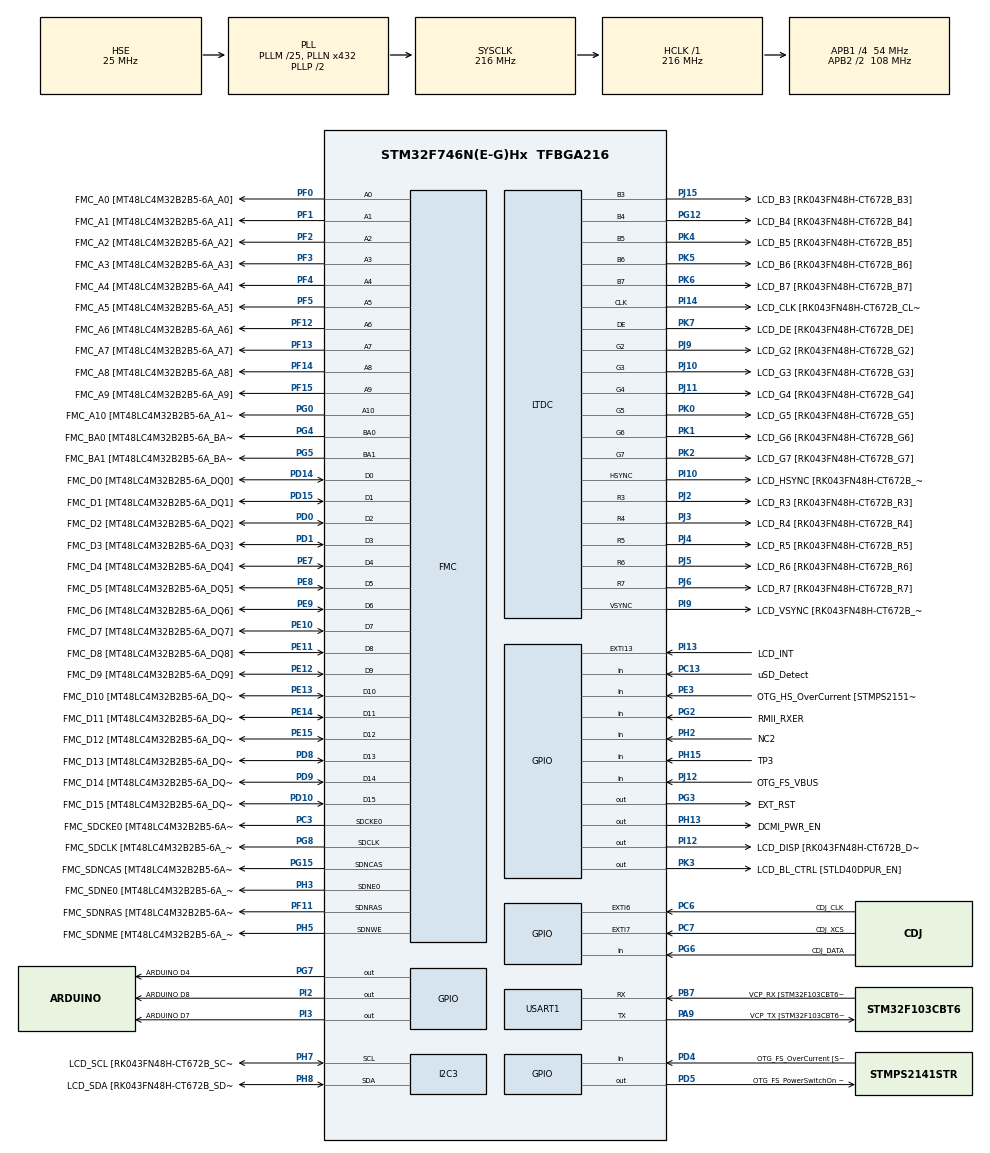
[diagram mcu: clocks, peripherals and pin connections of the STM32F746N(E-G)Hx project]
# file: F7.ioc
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CORTEX_M7.CPU_DCache=Enabled
CORTEX_M7.CPU_ICache=Enabled
FMC.CASLatency1=FMC_SDRAM_CAS_LATENCY_2
FMC.ExitSelfRefreshDelay1=6
FMC.LoadToActiveDelay1=2
FMC.RCDDelay1=2
FMC.RPDelay1=2
FMC.ReadBurst1=FMC_SDRAM_RBURST_ENABLE
FMC.RowCycleDelay1=6
FMC.SelfRefreshTime1=4
FMC.WriteRecoveryTime1=2
I2C3.Timing=0x20404768
LTDC.ActiveH=272
LTDC.ActiveW=480
LTDC.Alpha_L0=255
LTDC.Alpha_L1=255
LTDC.HBP=13
LTDC.HFP=32
LTDC.HSync=41
LTDC.Layers=1
LTDC.VSync=10
LTDC.WindowX1_L0=239
LTDC.WindowX1_L1=239
LTDC.WindowY1_L0=239
LTDC.WindowY1_L1=239
Mcu.Family=STM32F7
Mcu.Name=STM32F746N(E-G)Hx
Mcu.Package=TFBGA216
NVIC.EXTI9_5_IRQn=true\:0\:0\:false\:false\:true
NVIC.PriorityGroup=NVIC_PRIORITYGROUP_4
PA0/WKUP.GPIO_Label=ARDUINO A0
PA0/WKUP.GPIO_Mode=GPIO_MODE_ANALOG
PA0/WKUP.GPIO_PuPd=GPIO_NOPULL
PA0/WKUP.Signal=ADCx_IN0
PA1.GPIO_Label=RMII_REF_CLK [LAN8742A-CZ-TR_REFCLK0]
PA1.Signal=ETH_REF_CLK
PA10.GPIO_Label=OTG_FS_ID
PA10.Signal=USB_OTG_FS_ID
PA11.GPIO_Label=OTG_FS_N
PA11.Signal=USB_OTG_FS_DM
PA12.GPIO_Label=OTG_FS_P
PA12.Signal=USB_OTG_FS_DP
PA13.GPIO_Label=SWDIO
PA13.Signal=SYS_JTMS-SWDIO
PA14.GPIO_Label=SWCLK
PA14.Signal=SYS_JTCK-SWCLK
PA15.GPIO_Label=ARDUINO PWM/D9
PA15.GPIO_ModeDefaultPP=GPIO_MODE_AF_PP
PA15.GPIO_PuPd=GPIO_NOPULL
PA15.GPIO_Speed=GPIO_SPEED_FREQ_LOW
PA15.Signal=S_TIM2_CH1_ETR
PA2.GPIO_Label=RMII_MDIO [LAN8742A-CZ-TR_MDIO]
PA2.Signal=ETH_MDIO
PA3.GPIO_Label=ULPI_D0 [USB3320C-EZK_D0]
PA3.Signal=USB_OTG_HS_ULPI_D0
PA4.GPIO_Label=DCMI_HSYNC
PA4.Signal=DCMI_HSYNC
PA5.GPIO_Label=ULPI_CLK [USB3320C-EZK_CLKOUT]
PA5.Signal=USB_OTG_HS_ULPI_CK
PA6.Signal=DCMI_PIXCLK
PA7.GPIO_Label=RMII_CRS_DV [LAN8742A-CZ-TR_CRS_DV]
PA7.Signal=ETH_CRS_DV
PA8.GPIO_Label=ARDUINO PWM/D5
PA8.GPIO_ModeDefaultPP=GPIO_MODE_AF_PP
PA8.GPIO_PuPd=GPIO_NOPULL
PA8.GPIO_Speed=GPIO_SPEED_FREQ_LOW
PA8.Signal=S_TIM1_CH1
PA9.GPIO_Label=VCP_TX [STM32F103CBT6_PA3]
PA9.GPIO_Mode=GPIO_MODE_AF_PP
PA9.GPIO_PuPd=GPIO_NOPULL
PA9.GPIO_Speed=GPIO_SPEED_FREQ_LOW
PA9.Mode=Asynchronous
PA9.Signal=USART1_TX
PB0.GPIO_Label=ULPI_D1 [USB3320C-EZK_D1]
PB0.Signal=USB_OTG_HS_ULPI_D1
PB1.GPIO_Label=ULPI_D2 [USB3320C-EZK_D2]
PB1.Signal=USB_OTG_HS_ULPI_D2
PB10.GPIO_Label=ULPI_D3 [USB3320C-EZK_D3]
PB10.Signal=USB_OTG_HS_ULPI_D3
PB11.GPIO_Label=ULPI_D4 [USB3320C-EZK_D4]
PB11.Signal=USB_OTG_HS_ULPI_D4
PB12.GPIO_Label=ULPI_D5 [USB3320C-EZK_D5]
PB12.Signal=USB_OTG_HS_ULPI_D5
PB13.GPIO_Label=ULPI_D6 [USB3320C-EZK_D6]
PB13.Signal=USB_OTG_HS_ULPI_D6
PB14.GPIO_Label=ARDUINO MISO/D12
PB14.GPIO_Mode=GPIO_MODE_AF_PP
PB14.GPIO_PuPd=GPIO_NOPULL
PB14.GPIO_Speed=GPIO_SPEED_FREQ_LOW
PB14.Signal=SPI2_MISO
PB15.GPIO_Label=ARDUINO MOSI/PWM/D11
PB15.GPIO_Mode=GPIO_MODE_AF_PP
PB15.GPIO_PuPd=GPIO_NOPULL
PB15.GPIO_Speed=GPIO_SPEED_FREQ_LOW
PB15.Signal=SPI2_MOSI
PB2.Signal=QUADSPI_CLK
PB3.GPIO_Label=SWO
PB3.Signal=SYS_JTDO-SWO
PB4.GPIO_Label=ARDUINO PWM/D3
PB4.GPIO_ModeDefaultPP=GPIO_MODE_AF_PP
PB4.GPIO_PuPd=GPIO_NOPULL
PB4.GPIO_Speed=GPIO_SPEED_FREQ_LOW
PB4.Signal=S_TIM3_CH1
PB5.GPIO_Label=ULPI_D7 [USB3320C-EZK_D7]
PB5.Signal=USB_OTG_HS_ULPI_D7
PB6.GPIO_Label=QSPI_NCS [N25Q128A13EF840E_S]
PB6.Signal=QUADSPI_BK1_NCS
PB7.GPIO_Label=VCP_RX [STM32F103CBT6_PA2]
PB7.GPIO_Mode=GPIO_MODE_AF_PP
PB7.GPIO_PuPd=GPIO_NOPULL
PB7.GPIO_Speed=GPIO_SPEED_FREQ_LOW
PB7.Mode=Asynchronous
PB7.Signal=USART1_RX
PB8.GPIO_Label=ARDUINO SCL/D15
PB8.GPIO_Mode=GPIO_MODE_AF_OD
PB8.GPIO_PuPd=GPIO_NOPULL
PB8.GPIO_Speed=GPIO_SPEED_FREQ_LOW
PB8.Signal=I2C1_SCL
PB9.GPIO_Label=ARDUINO SDA/D14
PB9.GPIO_Mode=GPIO_MODE_AF_OD
PB9.GPIO_PuPd=GPIO_NOPULL
PB9.GPIO_Speed=GPIO_SPEED_FREQ_LOW
PB9.Signal=I2C1_SDA
PC0.GPIO_Label=ULPI_STP [USB3320C-EZK_STP]
PC0.Signal=USB_OTG_HS_ULPI_STP
PC1.GPIO_Label=RMII_MDC [LAN8742A-CZ-TR_MDC]
PC1.Signal=ETH_MDC
PC10.GPIO_Label=SDMMC_D2
PC10.Signal=SDMMC1_D2
PC11.GPIO_Label=SDMMC_D3
PC11.Signal=SDMMC1_D3
PC12.GPIO_Label=SDMMC_CK
PC12.Signal=SDMMC1_CK
PC13.GPIO_Label=uSD_Detect
PC13.Signal=GPIO_Input
PC14/OSC32_IN.GPIO_Label=RCC_OSC32_IN
PC14/OSC32_IN.Signal=RCC_OSC32_IN
PC15/OSC32_OUT.GPIO_Label=RCC_OSC32_OUT
PC15/OSC32_OUT.Signal=RCC_OSC32_OUT
PC2.GPIO_Label=ULPI_DIR [USB3320C-EZK_DIR]
PC2.Signal=USB_OTG_HS_ULPI_DIR
PC3.GPIO_Label=FMC_SDCKE0 [MT48LC4M32B2B5-6A_CKE]
PC3.Mode=SdramChipSelect1_1
PC3.Signal=FMC_SDCKE0
PC4.GPIO_Label=RMII_RXD0 [LAN8742A-CZ-TR_RXD0]
PC4.Signal=ETH_RXD0
PC5.GPIO_Label=RMII_RXD1 [LAN8742A-CZ-TR_RXD1]
PC5.Signal=ETH_RXD1
PC6.GPIO_Label=CDJ_CLK
PC6.GPIO_ModeDefaultEXTI=GPIO_MODE_IT_RISING
PC6.GPIO_PuPd=GPIO_PULLUP
PC6.Signal=GPXTI6
PC7.GPIO_Label=CDJ_XCS
PC7.GPIO_ModeDefaultEXTI=GPIO_MODE_IT_FALLING
PC7.GPIO_PuPd=GPIO_PULLUP
PC7.Signal=GPXTI7
PC8.Signal=SDMMC1_D0
PC9.Signal=SDMMC1_D1
PD0.GPIO_Label=FMC_D2 [MT48LC4M32B2B5-6A_DQ2]
PD0.Signal=FMC_D2_DA2
PD1.GPIO_Label=FMC_D3 [MT48LC4M32B2B5-6A_DQ3]
PD1.Signal=FMC_D3_DA3
PD10.GPIO_Label=FMC_D15 [MT48LC4M32B2B5-6A_DQ15]
PD10.Signal=FMC_D15_DA15
PD11.GPIO_Label=QSPI_D0 [N25Q128A13EF840E_DQ0]
PD11.Signal=QUADSPI_BK1_IO0
PD12.GPIO_Label=QSPI_D1 [N25Q128A13EF840E_DQ1]
PD12.Signal=QUADSPI_BK1_IO1
PD13.GPIO_Label=QSPI_D3 [N25Q128A13EF840E_DQ3]
PD13.Signal=QUADSPI_BK1_IO3
PD14.GPIO_Label=FMC_D0 [MT48LC4M32B2B5-6A_DQ0]
PD14.Signal=FMC_D0_DA0
PD15.GPIO_Label=FMC_D1 [MT48LC4M32B2B5-6A_DQ1]
PD15.Signal=FMC_D1_DA1
PD2.GPIO_Label=SDMMC_D0
PD2.Signal=SDMMC1_CMD
PD3.GPIO_Label=DCMI_D5
PD3.Signal=DCMI_D5
PD4.GPIO_Label=OTG_FS_OverCurrent [STMPS2141STR_Fault]
PD4.Signal=GPIO_Input
PD5.GPIO_Label=OTG_FS_PowerSwitchOn [STMPS2141STR_EN]
PD5.PinState=GPIO_PIN_SET
PD5.Signal=GPIO_Output
PD7.GPIO_Label=SPDIF_RX0 [74LVC1G04SE_4]
PD7.Signal=SPDIFRX_IN0
PD8.GPIO_Label=FMC_D13 [MT48LC4M32B2B5-6A_DQ13]
PD8.Signal=FMC_D13_DA13
PD9.GPIO_Label=FMC_D14 [MT48LC4M32B2B5-6A_DQ14]
PD9.Signal=FMC_D14_DA14
PE0.GPIO_Label=FMC_NBL0 [MT48LC4M32B2B5-6A_DQM0]
PE0.Signal=FMC_NBL0
PE1.GPIO_Label=FMC_NBL1 [MT48LC4M32B2B5-6A_DQM1]
PE1.Signal=FMC_NBL1
PE10.GPIO_Label=FMC_D7 [MT48LC4M32B2B5-6A_DQ7]
PE10.Signal=FMC_D7_DA7
PE11.GPIO_Label=FMC_D8 [MT48LC4M32B2B5-6A_DQ8]
PE11.Signal=FMC_D8_DA8
PE12.GPIO_Label=FMC_D9 [MT48LC4M32B2B5-6A_DQ9]
PE12.Signal=FMC_D9_DA9
PE13.GPIO_Label=FMC_D10 [MT48LC4M32B2B5-6A_DQ10]
PE13.Signal=FMC_D10_DA10
PE14.GPIO_Label=FMC_D11 [MT48LC4M32B2B5-6A_DQ11]
PE14.Signal=FMC_D11_DA11
PE15.GPIO_Label=FMC_D12 [MT48LC4M32B2B5-6A_DQ12]
PE15.Signal=FMC_D12_DA12
PE2.GPIO_Label=QSPI_D2 [N25Q128A13EF840E_DQ2]
PE2.Signal=QUADSPI_BK1_IO2
PE3.GPIO_Label=OTG_HS_OverCurrent [STMPS2151STR_FAULT]
PE3.Signal=GPIO_Input
PE4.GPIO_Label=LCD_B0 [RK043FN48H-CT672B_B0]
PE4.Signal=LTDC_B0
PE5.GPIO_Label=DCMI_D6
PE5.Signal=DCMI_D6
PE6.GPIO_Label=DCMI_D7
PE6.Signal=DCMI_D7
PE7.GPIO_Label=FMC_D4 [MT48LC4M32B2B5-6A_DQ4]
PE7.Signal=FMC_D4_DA4
PE8.GPIO_Label=FMC_D5 [MT48LC4M32B2B5-6A_DQ5]
PE8.Signal=FMC_D5_DA5
PE9.GPIO_Label=FMC_D6 [MT48LC4M32B2B5-6A_DQ6]
PE9.Signal=FMC_D6_DA6
PF0.GPIO_Label=FMC_A0 [MT48LC4M32B2B5-6A_A0]
PF0.Signal=FMC_A0
PF1.GPIO_Label=FMC_A1 [MT48LC4M32B2B5-6A_A1]
PF1.Signal=FMC_A1
PF10.GPIO_Label=ARDUINO A1
PF10.GPIO_Mode=GPIO_MODE_ANALOG
PF10.GPIO_PuPd=GPIO_NOPULL
PF10.Signal=ADC3_IN8
PF11.GPIO_Label=FMC_SDNRAS [MT48LC4M32B2B5-6A_RAS]
PF11.Signal=FMC_SDNRAS
PF12.GPIO_Label=FMC_A6 [MT48LC4M32B2B5-6A_A6]
PF12.Signal=FMC_A6
PF13.GPIO_Label=FMC_A7 [MT48LC4M32B2B5-6A_A7]
PF13.Signal=FMC_A7
PF14.GPIO_Label=FMC_A8 [MT48LC4M32B2B5-6A_A8]
PF14.Signal=FMC_A8
PF15.GPIO_Label=FMC_A9 [MT48LC4M32B2B5-6A_A9]
PF15.Signal=FMC_A9
PF2.GPIO_Label=FMC_A2 [MT48LC4M32B2B5-6A_A2]
PF2.Signal=FMC_A2
PF3.GPIO_Label=FMC_A3 [MT48LC4M32B2B5-6A_A3]
PF3.Signal=FMC_A3
PF4.GPIO_Label=FMC_A4 [MT48LC4M32B2B5-6A_A4]
PF4.Signal=FMC_A4
PF5.GPIO_Label=FMC_A5 [MT48LC4M32B2B5-6A_A5]
PF5.Signal=FMC_A5
PF6.GPIO_Label=ARDUINO A5
PF6.GPIO_Mode=GPIO_MODE_ANALOG
PF6.GPIO_PuPd=GPIO_NOPULL
PF6.Signal=ADC3_IN4
PF7.GPIO_Label=ARDUINO A4
PF7.GPIO_Mode=GPIO_MODE_ANALOG
PF7.GPIO_PuPd=GPIO_NOPULL
PF7.Signal=ADC3_IN5
PF8.GPIO_Label=ARDUINO A3
PF8.GPIO_Mode=GPIO_MODE_ANALOG
PF8.GPIO_PuPd=GPIO_NOPULL
PF8.Signal=ADC3_IN6
PF9.GPIO_Label=ARDUINO A2
PF9.GPIO_Mode=GPIO_MODE_ANALOG
PF9.GPIO_PuPd=GPIO_NOPULL
PF9.Signal=ADC3_IN7
PG0.GPIO_Label=FMC_A10 [MT48LC4M32B2B5-6A_A10]
PG0.Signal=FMC_A10
PG1.GPIO_Label=FMC_A11 [MT48LC4M32B2B5-6A_A11]
PG1.Signal=FMC_A11
PG10.GPIO_Label=SAI2_SDB [WM8994ECS/R_ADCDAT1]
PG10.Signal=SAI2_SD_B
PG11.GPIO_Label=RMII_TX_EN [LAN8742A-CZ-TR_TXEN]
PG11.Signal=ETH_TX_EN
PG12.GPIO_Label=LCD_B4 [RK043FN48H-CT672B_B4]
PG12.Mode=RGB565
PG12.Signal=LTDC_B4
PG13.GPIO_Label=RMII_TXD0 [LAN8742A-CZ-TR_TXD0]
PG13.Signal=ETH_TXD0
PG14.GPIO_Label=RMII_TXD1 [LAN8742A-CZ-TR_TXD1]
PG14.Signal=ETH_TXD1
PG15.GPIO_Label=FMC_SDNCAS [MT48LC4M32B2B5-6A_CAS]
PG15.Signal=FMC_SDNCAS
PG2.GPIO_Label=RMII_RXER
PG2.Signal=GPIO_Input
PG3.GPIO_Label=EXT_RST
PG3.Signal=GPIO_Output
PG4.GPIO_Label=FMC_BA0 [MT48LC4M32B2B5-6A_BA0]
PG4.Signal=FMC_A14_BA0
PG5.GPIO_Label=FMC_BA1 [MT48LC4M32B2B5-6A_BA1]
PG5.Signal=FMC_A15_BA1
PG6.GPIO_Label=CDJ_DATA
PG6.GPIO_PuPd=GPIO_PULLUP
PG6.Signal=GPIO_Input
PG7.GPIO_Label=ARDUINO D4
PG7.Signal=GPIO_Output
PG8.GPIO_Label=FMC_SDCLK [MT48LC4M32B2B5-6A_CLK]
PG8.Signal=FMC_SDCLK
PG9.GPIO_Label=DCMI_VSYNC
PG9.Signal=DCMI_VSYNC
PH0/OSC_IN.GPIO_Label=OSC_25M [NZ2520SB-25.00M_OUT]
PH0/OSC_IN.Mode=HSE-External-Oscillator
PH0/OSC_IN.Signal=RCC_OSC_IN
PH1/OSC_OUT.Mode=HSE-External-Oscillator
PH1/OSC_OUT.Signal=RCC_OSC_OUT
PH10.GPIO_Label=DCMI_D1
PH10.Signal=DCMI_D1
PH11.GPIO_Label=DCMI_D2
PH11.Signal=DCMI_D2
PH12.GPIO_Label=DCMI_D3
PH12.Signal=DCMI_D3
PH13.GPIO_Label=DCMI_PWR_EN
PH13.Signal=GPIO_Output
PH14.GPIO_Label=DCMI_D4
PH14.Signal=DCMI_D4
PH15.GPIO_Label=TP3
PH15.Signal=GPIO_Input
PH2.GPIO_Label=NC2
PH2.Signal=GPIO_Input
PH3.GPIO_Label=FMC_SDNE0 [MT48LC4M32B2B5-6A_CS]
PH3.Mode=SdramChipSelect1_1
PH3.Signal=FMC_SDNE0
PH4.GPIO_Label=ULPI_NXT [USB3320C-EZK_NXT]
PH4.Signal=USB_OTG_HS_ULPI_NXT
PH5.GPIO_Label=FMC_SDNME [MT48LC4M32B2B5-6A_WE]
PH5.Signal=FMC_SDNWE
PH6.GPIO_Label=ARDUINO PWM/D6
PH6.Signal=S_TIM12_CH1
PH7.GPIO_Label=LCD_SCL [RK043FN48H-CT672B_SCL]
PH7.Mode=I2C
PH7.Signal=I2C3_SCL
PH8.GPIO_Label=LCD_SDA [RK043FN48H-CT672B_SDA]
PH8.Mode=I2C
PH8.Signal=I2C3_SDA
PH9.GPIO_Label=DCMI_D0
PH9.Signal=DCMI_D0
PI0.GPIO_Label=ARDUINO PWM/CS/D10
PI0.GPIO_ModeDefaultPP=GPIO_MODE_AF_PP
PI0.GPIO_PuPd=GPIO_NOPULL
PI0.GPIO_Speed=GPIO_SPEED_FREQ_LOW
PI0.Signal=S_TIM5_CH4
PI1.GPIO_Label=ARDUINO SCK/D13
PI1.GPIO_Mode=GPIO_MODE_AF_PP
PI1.GPIO_PuPd=GPIO_NOPULL
PI1.GPIO_Speed=GPIO_SPEED_FREQ_LOW
PI1.Signal=SPI2_SCK
PI10.GPIO_Label=LCD_HSYNC [RK043FN48H-CT672B_HSYNC]
PI10.Mode=RGB565
PI10.Signal=LTDC_HSYNC
PI12.GPIO_Label=LCD_DISP [RK043FN48H-CT672B_DISP] 
PI12.Signal=GPIO_Output
PI13.GPIO_Label=LCD_INT
PI13.GPIO_ModeDefaultEXTI=GPIO_MODE_EVT_RISING
PI13.Signal=GPXTI13
PI14.GPIO_Label=LCD_CLK [RK043FN48H-CT672B_CLK]
PI14.Mode=RGB565
PI14.Signal=LTDC_CLK
PI15.GPIO_Label=LCD_R0 [RK043FN48H-CT672B_R0]
PI15.Signal=LTDC_R0
PI2.GPIO_Label=ARDUINO D8
PI2.Signal=GPIO_Output
PI3.GPIO_Label=ARDUINO D7
PI3.Signal=GPIO_Output
PI4.GPIO_Label=SAI2_MCLKA [WM8994ECS/R_MCLK1]
PI4.Signal=SAI2_MCLK_A
PI5.GPIO_Label=SAI2_SCKA [WM8994ECS/R_BCLK1]
PI5.Signal=SAI2_SCK_A
PI6.GPIO_Label=SAI2_SDA [WM8994ECS/R_DACDAT1]
PI6.Signal=SAI2_SD_A
PI7.GPIO_Label=SAI2_FSA [WM8994ECS/R_LRCLK1]
PI7.Signal=SAI2_FS_A
PI8.GPIO_Label=NC1 [TP2]
PI8.Signal=RTC_TS
PI9.GPIO_Label=LCD_VSYNC [RK043FN48H-CT672B_VSYNC]
PI9.Mode=RGB565
PI9.Signal=LTDC_VSYNC
PJ0.GPIO_Label=LCD_R1 [RK043FN48H-CT672B_R1]
PJ0.Signal=LTDC_R1
PJ1.GPIO_Label=LCD_R2 [RK043FN48H-CT672B_R2]
PJ1.Signal=LTDC_R2
PJ10.GPIO_Label=LCD_G3 [RK043FN48H-CT672B_G3]
PJ10.Mode=RGB565
PJ10.Signal=LTDC_G3
PJ11.GPIO_Label=LCD_G4 [RK043FN48H-CT672B_G4]
PJ11.Mode=RGB565
PJ11.Signal=LTDC_G4
PJ12.GPIO_Label=OTG_FS_VBUS
PJ12.Signal=GPIO_Input
PJ13.GPIO_Label=LCD_B1 [RK043FN48H-CT672B_B1]
PJ13.Signal=LTDC_B1
PJ14.GPIO_Label=LCD_B2 [RK043FN48H-CT672B_B2]
PJ14.Signal=LTDC_B2
PJ15.GPIO_Label=LCD_B3 [RK043FN48H-CT672B_B3]
PJ15.Mode=RGB565
PJ15.Signal=LTDC_B3
PJ2.GPIO_Label=LCD_R3 [RK043FN48H-CT672B_R3]
PJ2.Mode=RGB565
PJ2.Signal=LTDC_R3
PJ3.GPIO_Label=LCD_R4 [RK043FN48H-CT672B_R4]
PJ3.Mode=RGB565
PJ3.Signal=LTDC_R4
PJ4.GPIO_Label=LCD_R5 [RK043FN48H-CT672B_R5]
PJ4.Mode=RGB565
PJ4.Signal=LTDC_R5
PJ5.GPIO_Label=LCD_R6 [RK043FN48H-CT672B_R6]
PJ5.Mode=RGB565
PJ5.Signal=LTDC_R6
PJ6.GPIO_Label=LCD_R7 [RK043FN48H-CT672B_R7]
PJ6.Mode=RGB565
PJ6.Signal=LTDC_R7
PJ7.GPIO_Label=LCD_G0 [RK043FN48H-CT672B_G0]
PJ7.Signal=LTDC_G0
PJ8.GPIO_Label=LCD_G1 [RK043FN48H-CT672B_G1]
PJ8.Signal=LTDC_G1
PJ9.GPIO_Label=LCD_G2 [RK043FN48H-CT672B_G2]
PJ9.Mode=RGB565
PJ9.Signal=LTDC_G2
PK0.GPIO_Label=LCD_G5 [RK043FN48H-CT672B_G5]
PK0.Mode=RGB565
PK0.Signal=LTDC_G5
PK1.GPIO_Label=LCD_G6 [RK043FN48H-CT672B_G6]
PK1.Mode=RGB565
PK1.Signal=LTDC_G6
PK2.GPIO_Label=LCD_G7 [RK043FN48H-CT672B_G7]
PK2.Mode=RGB565
PK2.Signal=LTDC_G7
PK3.GPIO_Label=LCD_BL_CTRL [STLD40DPUR_EN]
PK3.Signal=GPIO_Output
PK4.GPIO_Label=LCD_B5 [RK043FN48H-CT672B_B5]
PK4.Mode=RGB565
PK4.Signal=LTDC_B5
PK5.GPIO_Label=LCD_B6 [RK043FN48H-CT672B_B6]
PK5.Mode=RGB565
PK5.Signal=LTDC_B6
PK6.GPIO_Label=LCD_B7 [RK043FN48H-CT672B_B7]
PK6.Mode=RGB565
PK6.Signal=LTDC_B7
PK7.GPIO_Label=LCD_DE [RK043FN48H-CT672B_DE]
PK7.Mode=RGB565
PK7.Signal=LTDC_DE
ProjectManager.HeapSize=0x200
ProjectManager.StackSize=0x400
ProjectManager.TargetToolchain=MDK-ARM V5
RCC.AHBFreq_Value=216000000
RCC.APB1CLKDivider=RCC_HCLK_DIV4
RCC.APB1Freq_Value=54000000
RCC.APB1TimFreq_Value=108000000
RCC.APB2CLKDivider=RCC_HCLK_DIV2
RCC.APB2Freq_Value=108000000
RCC.APB2TimFreq_Value=216000000
RCC.CortexFreq_Value=216000000
RCC.HCLKFreq_Value=216000000
RCC.HSE_VALUE=25000000
RCC.HSI_VALUE=16000000
RCC.LSE_VALUE=32768
RCC.PLLI2SN=135
RCC.PLLI2SQ=3
RCC.PLLI2SQDiv=4
RCC.PLLM=25
RCC.PLLN=432
RCC.PLLQ=15
RCC.PLLSAIN=120
RCC.PLLSourceVirtual=RCC_PLLSOURCE_HSE
RCC.SAI2CLockSelection=RCC_SAI2CLKSOURCE_PLLI2S
RCC.SDMMCClockSelection=RCC_SDMMC1CLKSOURCE_CLK48
RCC.SYSCLKFreq_VALUE=216000000
RCC.SYSCLKSource=RCC_SYSCLKSOURCE_PLLCLK
RCC.USBFreq_Value=28800000
RCC.VCOOutputFreq_Value=432000000
SH.ADCx_IN0.0=ADC3_IN0
SH.FMC_A0.0=FMC_A0,11b-sda1
SH.FMC_A1.0=FMC_A1,11b-sda1
SH.FMC_A10.0=FMC_A10,11b-sda1
SH.FMC_A11.0=FMC_A11
SH.FMC_A14_BA0.0=FMC_BA0,FourSdramBanks1
SH.FMC_A15_BA1.0=FMC_BA1,FourSdramBanks1
SH.FMC_A2.0=FMC_A2,11b-sda1
SH.FMC_A3.0=FMC_A3,11b-sda1
SH.FMC_A4.0=FMC_A4,11b-sda1
SH.FMC_A5.0=FMC_A5,11b-sda1
SH.FMC_A6.0=FMC_A6,11b-sda1
SH.FMC_A7.0=FMC_A7,11b-sda1
SH.FMC_A8.0=FMC_A8,11b-sda1
SH.FMC_A9.0=FMC_A9,11b-sda1
SH.FMC_D0_DA0.0=FMC_D0,sd-16b-d1
SH.FMC_D10_DA10.0=FMC_D10,sd-16b-d1
SH.FMC_D11_DA11.0=FMC_D11,sd-16b-d1
SH.FMC_D12_DA12.0=FMC_D12,sd-16b-d1
SH.FMC_D13_DA13.0=FMC_D13,sd-16b-d1
SH.FMC_D14_DA14.0=FMC_D14,sd-16b-d1
SH.FMC_D15_DA15.0=FMC_D15,sd-16b-d1
SH.FMC_D1_DA1.0=FMC_D1,sd-16b-d1
SH.FMC_D2_DA2.0=FMC_D2,sd-16b-d1
SH.FMC_D3_DA3.0=FMC_D3,sd-16b-d1
SH.FMC_D4_DA4.0=FMC_D4,sd-16b-d1
SH.FMC_D5_DA5.0=FMC_D5,sd-16b-d1
SH.FMC_D6_DA6.0=FMC_D6,sd-16b-d1
SH.FMC_D7_DA7.0=FMC_D7,sd-16b-d1
SH.FMC_D8_DA8.0=FMC_D8,sd-16b-d1
SH.FMC_D9_DA9.0=FMC_D9,sd-16b-d1
SH.FMC_NBL0.0=FMC_NBL0
SH.FMC_NBL1.0=FMC_NBL1
SH.FMC_SDCLK.0=FMC_SDCLK,11b-sda1
SH.FMC_SDNCAS.0=FMC_SDNCAS,11b-sda1
SH.FMC_SDNRAS.0=FMC_SDNRAS,11b-sda1
SH.FMC_SDNWE.0=FMC_SDNWE,11b-sda1
SH.S_TIM12_CH1.0=TIM12_CH1
SH.S_TIM1_CH1.0=TIM1_CH1
SH.S_TIM2_CH1_ETR.0=TIM2_CH1
SH.S_TIM3_CH1.0=TIM3_CH1
SH.S_TIM5_CH4.0=TIM5_CH4
VP_DMA2D_VS_DMA2D.Mode=DMA2D_Activate
board=STM32F746G-DISCO

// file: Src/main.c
/**
  ******************************************************************************
  * File Name          : main.c
  * Description        : Main program body
  ******************************************************************************
  *
  * COPYRIGHT(c) 2017 STMicroelectronics
  *
  * Redistribution and use in source and binary forms, with or without modification,
  * are permitted provided that the following conditions are met:
  *   1. Redistributions of source code must retain the above copyright notice,
  *      this list of conditions and the following disclaimer.
  *   2. Redistributions in binary form must reproduce the above copyright notice,
  *      this list of conditions and the following disclaimer in the documentation
  *      and/or other materials provided with the distribution.
  *   3. Neither the name of STMicroelectronics nor the names of its contributors
  *      may be used to endorse or promote products derived from this software
  *      without specific prior written permission.
  *
  * THIS SOFTWARE IS PROVIDED BY THE COPYRIGHT HOLDERS AND CONTRIBUTORS "AS IS"
  * AND ANY EXPRESS OR IMPLIED WARRANTIES, INCLUDING, BUT NOT LIMITED TO, THE
  * IMPLIED WARRANTIES OF MERCHANTABILITY AND FITNESS FOR A PARTICULAR PURPOSE ARE
  * DISCLAIMED. IN NO EVENT SHALL THE COPYRIGHT HOLDER OR CONTRIBUTORS BE LIABLE
  * FOR ANY DIRECT, INDIRECT, INCIDENTAL, SPECIAL, EXEMPLARY, OR CONSEQUENTIAL
  * DAMAGES (INCLUDING, BUT NOT LIMITED TO, PROCUREMENT OF SUBSTITUTE GOODS OR
  * SERVICES; LOSS OF USE, DATA, OR PROFITS; OR BUSINESS INTERRUPTION) HOWEVER
  * CAUSED AND ON ANY THEORY OF LIABILITY, WHETHER IN CONTRACT, STRICT LIABILITY,
  * OR TORT (INCLUDING NEGLIGENCE OR OTHERWISE) ARISING IN ANY WAY OUT OF THE USE
  * OF THIS SOFTWARE, EVEN IF ADVISED OF THE POSSIBILITY OF SUCH DAMAGE.
  *
  ******************************************************************************
  */
#include "main.h"
#include "stm32f7xx_hal.h"

/* USER CODE BEGIN Includes */
#include <stdlib.h>
#include "stm32746g_discovery.h"
#include "stm32746g_discovery_lcd.h"
/* USER CODE END Includes */

DMA2D_HandleTypeDef hdma2d;

I2C_HandleTypeDef hi2c3;

LTDC_HandleTypeDef hltdc;

UART_HandleTypeDef huart1;

SDRAM_HandleTypeDef hsdram1;

/* USER CODE BEGIN PV */
/* Private variables ---------------------------------------------------------*/
#define LCD_FRAME_BUFFER    SDRAM_DEVICE_ADDR
uint8_t lcd_status = LCD_OK;
uint8_t tBuf[20]={0};
uint8_t buf[8][27] = {0};
uint8_t number_of_package = 0;
uint16_t clock_CNT = 0;

/* USER CODE END PV */

void SystemClock_Config(void);
void Error_Handler(void);
static void MX_GPIO_Init(void);
static void MX_DMA2D_Init(void);
static void MX_FMC_Init(void);
static void MX_LTDC_Init(void);
static void MX_I2C3_Init(void);
static void MX_USART1_UART_Init(void);

/* USER CODE BEGIN PFP */
/* Private function prototypes -----------------------------------------------*/

/* USER CODE END PFP */

int main(void)
{

  /* Enable I-Cache-------------------------------------------------------------*/
  SCB_EnableICache();

  /* Enable D-Cache-------------------------------------------------------------*/
  SCB_EnableDCache();

  /* MCU Configuration----------------------------------------------------------*/

  /* Reset of all peripherals, Initializes the Flash interface and the Systick. */
  HAL_Init();

  /* Configure the system clock */
  SystemClock_Config();

  /* Initialize all configured peripherals */
  MX_GPIO_Init();
  MX_DMA2D_Init();
  MX_FMC_Init();
  MX_LTDC_Init();
  MX_I2C3_Init();
  MX_USART1_UART_Init();

  /* USER CODE BEGIN 2 */

	lcd_status = BSP_LCD_Init();
	BSP_LCD_LayerDefaultInit(0,LCD_FRAME_BUFFER);

	BSP_LCD_SelectLayer(0);
	BSP_LCD_DisplayOn();
	BSP_LCD_SetTransparency(0, 255);
	BSP_LCD_SetTransparency(1, 0);
	BSP_LCD_Clear(LCD_COLOR_BLACK);
	BSP_LCD_SetBackColor(LCD_COLOR_BLACK);
	BSP_LCD_SetTextColor(LCD_COLOR_BLUE);
	BSP_LCD_SetFont(&Font8);

	uint16_t n = 0;
	uint16_t i = 0;
	uint16_t G = 0;

	uint8_t P = 7;
	uint8_t BT = 18;
	uint8_t T = 0;

  /* USER CODE END 2 */

  /* Infinite loop */
  /* USER CODE BEGIN WHILE */
  while (1)
  {
		for(i=0;i<27;i++)
		{
		if(i==0 | i==9 | i==19)
			{
			BSP_LCD_SetTextColor(LCD_COLOR_BLUE);
			}
		else if(i%2==0)
			{
			BSP_LCD_SetTextColor(LCD_COLOR_RED);
			}
		else
			{
			BSP_LCD_SetTextColor(LCD_COLOR_GREEN);
			}

		for(n=0;n<8;n++)
			{
			sprintf((char*)tBuf, "%3lu", buf[n][i]);
			BSP_LCD_DisplayStringAt(30*n+5,i*9,tBuf, LEFT_MODE);
			}
		}

		BSP_LCD_SetTextColor(LCD_COLOR_WHITE);

			sprintf((char*)tBuf, "%s", "PKG:");
			BSP_LCD_DisplayStringAt(390,80,tBuf, LEFT_MODE);
			sprintf((char*)tBuf, "%2lu", P);
			BSP_LCD_DisplayStringAt(415,80,tBuf, LEFT_MODE);

			sprintf((char*)tBuf, "%s", "BYTE:");
			BSP_LCD_DisplayStringAt(390,93,tBuf, LEFT_MODE);
			sprintf((char*)tBuf, "%2lu", BT);
			BSP_LCD_DisplayStringAt(425,93,tBuf, LEFT_MODE);

			G = 256*buf[7][10]+buf[7][11];
			sprintf((char*)tBuf, "%6lu", G);
			BSP_LCD_DisplayStringAt(390,106,tBuf, LEFT_MODE);

		for(n=0;n<8;n++)
			{
			sprintf((char*)tBuf, "%1lu", buf[P][BT]/128);
			BSP_LCD_DisplayStringAt(8*n+300,BT*9,tBuf, LEFT_MODE);
			buf[P][BT] = buf[P][BT]<<1;
			}

		BSP_LCD_SetTextColor(LCD_COLOR_BLACK);
		BSP_LCD_DrawLine(455, 270, 455, 0);
		BSP_LCD_DrawLine(460, 270, 460, 0);
		BSP_LCD_DrawLine(465, 270, 465, 0);
		BSP_LCD_DrawLine(470, 270, 470, 0);
		BSP_LCD_DrawLine(475, 270, 475, 0);
		BSP_LCD_SetTextColor(LCD_COLOR_RED);
		BSP_LCD_DrawLine(455, 270, 455, 270-buf[7][2]);
		BSP_LCD_DrawLine(460, 270, 460, 270-buf[7][3]);
		BSP_LCD_SetTextColor(LCD_COLOR_GREEN);
		BSP_LCD_DrawLine(465, 270, 465, 270-buf[7][4]);
		BSP_LCD_SetTextColor(LCD_COLOR_WHITE);
		//BSP_LCD_DrawLine(470, 270, 470, 270-buf[7][10]);
		//BSP_LCD_DrawLine(475, 270, 475, 270-buf[7][11]);

		/*
		BSP_LCD_SetTextColor(LCD_COLOR_BLACK);
		BSP_LCD_FillRect(320, 234, 100, 7);

		for(n=0;n<700;n++)
			{
			T = buf[(n/7)/24][(n/7)%24+1]<<((n%7)+1);
			T = T/128;
			if(T==1)
				{
				BSP_LCD_DrawPixel(320+n/7,240-n%7,0xFFFFFFFF);
				}
			}

	*/
		HAL_Delay(50);

  /* USER CODE END WHILE */

  }

}

/** System Clock Configuration
*/
void SystemClock_Config(void)
{

  RCC_OscInitTypeDef RCC_OscInitStruct;
  RCC_ClkInitTypeDef RCC_ClkInitStruct;
  RCC_PeriphCLKInitTypeDef PeriphClkInitStruct;

    /**Configure the main internal regulator output voltage
    */
  __HAL_RCC_PWR_CLK_ENABLE();

  __HAL_PWR_VOLTAGESCALING_CONFIG(PWR_REGULATOR_VOLTAGE_SCALE1);

    /**Initializes the CPU, AHB and APB busses clocks
    */
  RCC_OscInitStruct.OscillatorType = RCC_OSCILLATORTYPE_HSE;
  RCC_OscInitStruct.HSEState = RCC_HSE_ON;
  RCC_OscInitStruct.PLL.PLLState = RCC_PLL_ON;
  RCC_OscInitStruct.PLL.PLLSource = RCC_PLLSOURCE_HSE;
  RCC_OscInitStruct.PLL.PLLM = 25;
  RCC_OscInitStruct.PLL.PLLN = 432;
  RCC_OscInitStruct.PLL.PLLP = RCC_PLLP_DIV2;
  RCC_OscInitStruct.PLL.PLLQ = 15;
  if (HAL_RCC_OscConfig(&RCC_OscInitStruct) != HAL_OK)
  {
    Error_Handler();
  }

    /**Activate the Over-Drive mode
    */
  if (HAL_PWREx_EnableOverDrive() != HAL_OK)
  {
    Error_Handler();
  }

    /**Initializes the CPU, AHB and APB busses clocks
    */
  RCC_ClkInitStruct.ClockType = RCC_CLOCKTYPE_HCLK|RCC_CLOCKTYPE_SYSCLK
                              |RCC_CLOCKTYPE_PCLK1|RCC_CLOCKTYPE_PCLK2;
  RCC_ClkInitStruct.SYSCLKSource = RCC_SYSCLKSOURCE_PLLCLK;
  RCC_ClkInitStruct.AHBCLKDivider = RCC_SYSCLK_DIV1;
  RCC_ClkInitStruct.APB1CLKDivider = RCC_HCLK_DIV4;
  RCC_ClkInitStruct.APB2CLKDivider = RCC_HCLK_DIV2;

  if (HAL_RCC_ClockConfig(&RCC_ClkInitStruct, FLASH_LATENCY_7) != HAL_OK)
  {
    Error_Handler();
  }

  PeriphClkInitStruct.PeriphClockSelection = RCC_PERIPHCLK_LTDC|RCC_PERIPHCLK_USART1
                              |RCC_PERIPHCLK_I2C3;
  PeriphClkInitStruct.PLLSAI.PLLSAIN = 120;
  PeriphClkInitStruct.PLLSAI.PLLSAIR = 2;
  PeriphClkInitStruct.PLLSAI.PLLSAIQ = 2;
  PeriphClkInitStruct.PLLSAI.PLLSAIP = RCC_PLLSAIP_DIV2;
  PeriphClkInitStruct.PLLSAIDivQ = 1;
  PeriphClkInitStruct.PLLSAIDivR = RCC_PLLSAIDIVR_2;
  PeriphClkInitStruct.Usart1ClockSelection = RCC_USART1CLKSOURCE_PCLK2;
  PeriphClkInitStruct.I2c3ClockSelection = RCC_I2C3CLKSOURCE_PCLK1;
  if (HAL_RCCEx_PeriphCLKConfig(&PeriphClkInitStruct) != HAL_OK)
  {
    Error_Handler();
  }

    /**Configure the Systick interrupt time
    */
  HAL_SYSTICK_Config(HAL_RCC_GetHCLKFreq()/1000);

    /**Configure the Systick
    */
  HAL_SYSTICK_CLKSourceConfig(SYSTICK_CLKSOURCE_HCLK);

  /* SysTick_IRQn interrupt configuration */
  HAL_NVIC_SetPriority(SysTick_IRQn, 0, 0);
}

/* DMA2D init function */
static void MX_DMA2D_Init(void)
{

  hdma2d.Instance = DMA2D;
  hdma2d.Init.Mode = DMA2D_M2M;
  hdma2d.Init.ColorMode = DMA2D_OUTPUT_ARGB8888;
  hdma2d.Init.OutputOffset = 0;
  hdma2d.LayerCfg[1].InputOffset = 0;
  hdma2d.LayerCfg[1].InputColorMode = DMA2D_INPUT_ARGB8888;
  hdma2d.LayerCfg[1].AlphaMode = DMA2D_NO_MODIF_ALPHA;
  hdma2d.LayerCfg[1].InputAlpha = 0;
  if (HAL_DMA2D_Init(&hdma2d) != HAL_OK)
  {
    Error_Handler();
  }

  if (HAL_DMA2D_ConfigLayer(&hdma2d, 1) != HAL_OK)
  {
    Error_Handler();
  }

}

/* I2C3 init function */
static void MX_I2C3_Init(void)
{

  hi2c3.Instance = I2C3;
  hi2c3.Init.Timing = 0x20404768;
  hi2c3.Init.OwnAddress1 = 0;
  hi2c3.Init.AddressingMode = I2C_ADDRESSINGMODE_7BIT;
  hi2c3.Init.DualAddressMode = I2C_DUALADDRESS_DISABLE;
  hi2c3.Init.OwnAddress2 = 0;
  hi2c3.Init.OwnAddress2Masks = I2C_OA2_NOMASK;
  hi2c3.Init.GeneralCallMode = I2C_GENERALCALL_DISABLE;
  hi2c3.Init.NoStretchMode = I2C_NOSTRETCH_DISABLE;
  if (HAL_I2C_Init(&hi2c3) != HAL_OK)
  {
    Error_Handler();
  }

    /**Configure Analogue filter
    */
  if (HAL_I2CEx_ConfigAnalogFilter(&hi2c3, I2C_ANALOGFILTER_ENABLE) != HAL_OK)
  {
    Error_Handler();
  }

}

/* LTDC init function */
static void MX_LTDC_Init(void)
{

  LTDC_LayerCfgTypeDef pLayerCfg;
  LTDC_LayerCfgTypeDef pLayerCfg1;

  hltdc.Instance = LTDC;
  hltdc.Init.HSPolarity = LTDC_HSPOLARITY_AL;
  hltdc.Init.VSPolarity = LTDC_VSPOLARITY_AL;
  hltdc.Init.DEPolarity = LTDC_DEPOLARITY_AL;
  hltdc.Init.PCPolarity = LTDC_PCPOLARITY_IPC;
  hltdc.Init.HorizontalSync = 40;
  hltdc.Init.VerticalSync = 9;
  hltdc.Init.AccumulatedHBP = 53;
  hltdc.Init.AccumulatedVBP = 11;
  hltdc.Init.AccumulatedActiveW = 533;
  hltdc.Init.AccumulatedActiveH = 283;
  hltdc.Init.TotalWidth = 565;
  hltdc.Init.TotalHeigh = 285;
  hltdc.Init.Backcolor.Blue = 0;
  hltdc.Init.Backcolor.Green = 0;
  hltdc.Init.Backcolor.Red = 0;
  if (HAL_LTDC_Init(&hltdc) != HAL_OK)
  {
    Error_Handler();
  }

  pLayerCfg.WindowX0 = 0;
  pLayerCfg.WindowX1 = 239;
  pLayerCfg.WindowY0 = 0;
  pLayerCfg.WindowY1 = 239;
  pLayerCfg.PixelFormat = LTDC_PIXEL_FORMAT_RGB565;
  pLayerCfg.Alpha = 255;
  pLayerCfg.Alpha0 = 0;
  pLayerCfg.BlendingFactor1 = LTDC_BLENDING_FACTOR1_CA;
  pLayerCfg.BlendingFactor2 = LTDC_BLENDING_FACTOR2_CA;
  pLayerCfg.FBStartAdress = 0;
  pLayerCfg.ImageWidth = 0;
  pLayerCfg.ImageHeight = 0;
  pLayerCfg.Backcolor.Blue = 0;
  pLayerCfg.Backcolor.Green = 0;
  pLayerCfg.Backcolor.Red = 0;
  if (HAL_LTDC_ConfigLayer(&hltdc, &pLayerCfg, 0) != HAL_OK)
  {
    Error_Handler();
  }

  pLayerCfg1.WindowX0 = 0;
  pLayerCfg1.WindowX1 = 239;
  pLayerCfg1.WindowY0 = 0;
  pLayerCfg1.WindowY1 = 239;
  pLayerCfg1.PixelFormat = LTDC_PIXEL_FORMAT_RGB565;
  pLayerCfg1.Alpha = 255;
  pLayerCfg1.Alpha0 = 0;
  pLayerCfg1.BlendingFactor1 = LTDC_BLENDING_FACTOR1_CA;
  pLayerCfg1.BlendingFactor2 = LTDC_BLENDING_FACTOR2_CA;
  pLayerCfg1.FBStartAdress = 0;
  pLayerCfg1.ImageWidth = 0;
  pLayerCfg1.ImageHeight = 0;
  pLayerCfg1.Backcolor.Blue = 0;
  pLayerCfg1.Backcolor.Green = 0;
  pLayerCfg1.Backcolor.Red = 0;
  if (HAL_LTDC_ConfigLayer(&hltdc, &pLayerCfg1, 1) != HAL_OK)
  {
    Error_Handler();
  }

}

/* USART1 init function */
static void MX_USART1_UART_Init(void)
{

  huart1.Instance = USART1;
  huart1.Init.BaudRate = 115200;
  huart1.Init.WordLength = UART_WORDLENGTH_7B;
  huart1.Init.StopBits = UART_STOPBITS_1;
  huart1.Init.Parity = UART_PARITY_NONE;
  huart1.Init.Mode = UART_MODE_TX_RX;
  huart1.Init.HwFlowCtl = UART_HWCONTROL_NONE;
  huart1.Init.OverSampling = UART_OVERSAMPLING_16;
  huart1.Init.OneBitSampling = UART_ONE_BIT_SAMPLE_DISABLE;
  huart1.AdvancedInit.AdvFeatureInit = UART_ADVFEATURE_NO_INIT;
  if (HAL_UART_Init(&huart1) != HAL_OK)
  {
    Error_Handler();
  }

}
/* FMC initialization function */
static void MX_FMC_Init(void)
{
  FMC_SDRAM_TimingTypeDef SdramTiming;

  /** Perform the SDRAM1 memory initialization sequence
  */
  hsdram1.Instance = FMC_SDRAM_DEVICE;
  /* hsdram1.Init */
  hsdram1.Init.SDBank = FMC_SDRAM_BANK1;
  hsdram1.Init.ColumnBitsNumber = FMC_SDRAM_COLUMN_BITS_NUM_8;
  hsdram1.Init.RowBitsNumber = FMC_SDRAM_ROW_BITS_NUM_11;
  hsdram1.Init.MemoryDataWidth = FMC_SDRAM_MEM_BUS_WIDTH_16;
  hsdram1.Init.InternalBankNumber = FMC_SDRAM_INTERN_BANKS_NUM_4;
  hsdram1.Init.CASLatency = FMC_SDRAM_CAS_LATENCY_2;
  hsdram1.Init.WriteProtection = FMC_SDRAM_WRITE_PROTECTION_DISABLE;
  hsdram1.Init.SDClockPeriod = FMC_SDRAM_CLOCK_DISABLE;
  hsdram1.Init.ReadBurst = FMC_SDRAM_RBURST_ENABLE;
  hsdram1.Init.ReadPipeDelay = FMC_SDRAM_RPIPE_DELAY_0;
  /* SdramTiming */
  SdramTiming.LoadToActiveDelay = 2;
  SdramTiming.ExitSelfRefreshDelay = 6;
  SdramTiming.SelfRefreshTime = 4;
  SdramTiming.RowCycleDelay = 6;
  SdramTiming.WriteRecoveryTime = 2;
  SdramTiming.RPDelay = 2;
  SdramTiming.RCDDelay = 2;

  if (HAL_SDRAM_Init(&hsdram1, &SdramTiming) != HAL_OK)
  {
    Error_Handler();
  }

}

/** Configure pins as
        * Analog
        * Input
        * Output
        * EVENT_OUT
        * EXTI
     PE2   ------> QUADSPI_BK1_IO2
     PG14   ------> ETH_TXD1
     PB8   ------> I2C1_SCL
     PB5   ------> USB_OTG_HS_ULPI_D7
     PB4   ------> S_TIM3_CH1
     PD7   ------> SPDIFRX_IN0
     PC12   ------> SDMMC1_CK
     PA15   ------> S_TIM2_CH1_ETR
     PE5   ------> DCMI_D6
     PE6   ------> DCMI_D7
     PG13   ------> ETH_TXD0
     PB9   ------> I2C1_SDA
     PB6   ------> QUADSPI_BK1_NCS
     PG11   ------> ETH_TX_EN
     PC11   ------> SDMMC1_D3
     PC10   ------> SDMMC1_D2
     PA12   ------> USB_OTG_FS_DP
     PI4   ------> SAI2_MCLK_A
     PG10   ------> SAI2_SD_B
     PD3   ------> DCMI_D5
     PA11   ------> USB_OTG_FS_DM
     PI5   ------> SAI2_SCK_A
     PI7   ------> SAI2_FS_A
     PI6   ------> SAI2_SD_A
     PG9   ------> DCMI_VSYNC
     PD2   ------> SDMMC1_CMD
     PI1   ------> SPI2_SCK
     PA10   ------> USB_OTG_FS_ID
     PH14   ------> DCMI_D4
     PI0   ------> S_TIM5_CH4
     PC9   ------> SDMMC1_D1
     PA8   ------> S_TIM1_CH1
     PC8   ------> SDMMC1_D0
     PH4   ------> USB_OTG_HS_ULPI_NXT
     PF7   ------> ADC3_IN5
     PF6   ------> ADC3_IN4
     PB13   ------> USB_OTG_HS_ULPI_D6
     PF10   ------> ADC3_IN8
     PF9   ------> ADC3_IN7
     PF8   ------> ADC3_IN6
     PB12   ------> USB_OTG_HS_ULPI_D5
     PC0   ------> USB_OTG_HS_ULPI_STP
     PC1   ------> ETH_MDC
     PC2   ------> USB_OTG_HS_ULPI_DIR
     PB2   ------> QUADSPI_CLK
     PD12   ------> QUADSPI_BK1_IO1
     PD13   ------> QUADSPI_BK1_IO3
     PH12   ------> DCMI_D3
     PA1   ------> ETH_REF_CLK
     PA0/WKUP   ------> ADCx_IN0
     PA4   ------> DCMI_HSYNC
     PC4   ------> ETH_RXD0
     PD11   ------> QUADSPI_BK1_IO0
     PH9   ------> DCMI_D0
     PH11   ------> DCMI_D2
     PA2   ------> ETH_MDIO
     PA6   ------> DCMI_PIXCLK
     PA5   ------> USB_OTG_HS_ULPI_CK
     PC5   ------> ETH_RXD1
     PB10   ------> USB_OTG_HS_ULPI_D3
     PH6   ------> S_TIM12_CH1
     PH10   ------> DCMI_D1
     PA3   ------> USB_OTG_HS_ULPI_D0
     PA7   ------> ETH_CRS_DV
     PB1   ------> USB_OTG_HS_ULPI_D2
     PB0   ------> USB_OTG_HS_ULPI_D1
     PB11   ------> USB_OTG_HS_ULPI_D4
     PB14   ------> SPI2_MISO
     PB15   ------> SPI2_MOSI
*/
static void MX_GPIO_Init(void)
{

  GPIO_InitTypeDef GPIO_InitStruct;

  /* GPIO Ports Clock Enable */
  __HAL_RCC_GPIOE_CLK_ENABLE();
  __HAL_RCC_GPIOG_CLK_ENABLE();
  __HAL_RCC_GPIOB_CLK_ENABLE();
  __HAL_RCC_GPIOD_CLK_ENABLE();
  __HAL_RCC_GPIOC_CLK_ENABLE();
  __HAL_RCC_GPIOA_CLK_ENABLE();
  __HAL_RCC_GPIOJ_CLK_ENABLE();
  __HAL_RCC_GPIOI_CLK_ENABLE();
  __HAL_RCC_GPIOK_CLK_ENABLE();
  __HAL_RCC_GPIOF_CLK_ENABLE();
  __HAL_RCC_GPIOH_CLK_ENABLE();

  /*Configure GPIO pin : OTG_HS_OverCurrent_Pin */
  GPIO_InitStruct.Pin = OTG_HS_OverCurrent_Pin;
  GPIO_InitStruct.Mode = GPIO_MODE_INPUT;
  GPIO_InitStruct.Pull = GPIO_NOPULL;
  HAL_GPIO_Init(OTG_HS_OverCurrent_GPIO_Port, &GPIO_InitStruct);

  /*Configure GPIO pin : QSPI_D2_Pin */
  GPIO_InitStruct.Pin = QSPI_D2_Pin;
  GPIO_InitStruct.Mode = GPIO_MODE_AF_PP;
  GPIO_InitStruct.Pull = GPIO_NOPULL;
  GPIO_InitStruct.Speed = GPIO_SPEED_FREQ_VERY_HIGH;
  GPIO_InitStruct.Alternate = GPIO_AF9_QUADSPI;
  HAL_GPIO_Init(QSPI_D2_GPIO_Port, &GPIO_InitStruct);

  /*Configure GPIO pins : RMII_TXD1_Pin RMII_TXD0_Pin RMII_TX_EN_Pin */
  GPIO_InitStruct.Pin = RMII_TXD1_Pin|RMII_TXD0_Pin|RMII_TX_EN_Pin;
  GPIO_InitStruct.Mode = GPIO_MODE_AF_PP;
  GPIO_InitStruct.Pull = GPIO_NOPULL;
  GPIO_InitStruct.Speed = GPIO_SPEED_FREQ_VERY_HIGH;
  GPIO_InitStruct.Alternate = GPIO_AF11_ETH;
  HAL_GPIO_Init(GPIOG, &GPIO_InitStruct);

  /*Configure GPIO pins : ARDUINO_SCL_D15_Pin ARDUINO_SDA_D14_Pin */
  GPIO_InitStruct.Pin = ARDUINO_SCL_D15_Pin|ARDUINO_SDA_D14_Pin;
  GPIO_InitStruct.Mode = GPIO_MODE_AF_OD;
  GPIO_InitStruct.Pull = GPIO_PULLUP;
  GPIO_InitStruct.Speed = GPIO_SPEED_FREQ_LOW;
  GPIO_InitStruct.Alternate = GPIO_AF4_I2C1;
  HAL_GPIO_Init(GPIOB, &GPIO_InitStruct);

  /*Configure GPIO pins : ULPI_D7_Pin ULPI_D6_Pin ULPI_D5_Pin ULPI_D3_Pin
                           ULPI_D2_Pin ULPI_D1_Pin ULPI_D4_Pin */
  GPIO_InitStruct.Pin = ULPI_D7_Pin|ULPI_D6_Pin|ULPI_D5_Pin|ULPI_D3_Pin
                          |ULPI_D2_Pin|ULPI_D1_Pin|ULPI_D4_Pin;
  GPIO_InitStruct.Mode = GPIO_MODE_AF_PP;
  GPIO_InitStruct.Pull = GPIO_NOPULL;
  GPIO_InitStruct.Speed = GPIO_SPEED_FREQ_VERY_HIGH;
  GPIO_InitStruct.Alternate = GPIO_AF10_OTG_HS;
  HAL_GPIO_Init(GPIOB, &GPIO_InitStruct);

  /*Configure GPIO pin : ARDUINO_PWM_D3_Pin */
  GPIO_InitStruct.Pin = ARDUINO_PWM_D3_Pin;
  GPIO_InitStruct.Mode = GPIO_MODE_AF_PP;
  GPIO_InitStruct.Pull = GPIO_NOPULL;
  GPIO_InitStruct.Speed = GPIO_SPEED_FREQ_LOW;
  GPIO_InitStruct.Alternate = GPIO_AF2_TIM3;
  HAL_GPIO_Init(ARDUINO_PWM_D3_GPIO_Port, &GPIO_InitStruct);

  /*Configure GPIO pin : SPDIF_RX0_Pin */
  GPIO_InitStruct.Pin = SPDIF_RX0_Pin;
  GPIO_InitStruct.Mode = GPIO_MODE_AF_PP;
  GPIO_InitStruct.Pull = GPIO_NOPULL;
  GPIO_InitStruct.Speed = GPIO_SPEED_FREQ_LOW;
  GPIO_InitStruct.Alternate = GPIO_AF8_SPDIFRX;
  HAL_GPIO_Init(SPDIF_RX0_GPIO_Port, &GPIO_InitStruct);

  /*Configure GPIO pins : SDMMC_CK_Pin SDMMC_D3_Pin SDMMC_D2_Pin PC9
                           PC8 */
  GPIO_InitStruct.Pin = SDMMC_CK_Pin|SDMMC_D3_Pin|SDMMC_D2_Pin|GPIO_PIN_9
                          |GPIO_PIN_8;
  GPIO_InitStruct.Mode = GPIO_MODE_AF_PP;
  GPIO_InitStruct.Pull = GPIO_NOPULL;
  GPIO_InitStruct.Speed = GPIO_SPEED_FREQ_VERY_HIGH;
  GPIO_InitStruct.Alternate = GPIO_AF12_SDMMC1;
  HAL_GPIO_Init(GPIOC, &GPIO_InitStruct);

  /*Configure GPIO pin : ARDUINO_PWM_D9_Pin */
  GPIO_InitStruct.Pin = ARDUINO_PWM_D9_Pin;
  GPIO_InitStruct.Mode = GPIO_MODE_AF_PP;
  GPIO_InitStruct.Pull = GPIO_NOPULL;
  GPIO_InitStruct.Speed = GPIO_SPEED_FREQ_LOW;
  GPIO_InitStruct.Alternate = GPIO_AF1_TIM2;
  HAL_GPIO_Init(ARDUINO_PWM_D9_GPIO_Port, &GPIO_InitStruct);

  /*Configure GPIO pins : DCMI_D6_Pin DCMI_D7_Pin */
  GPIO_InitStruct.Pin = DCMI_D6_Pin|DCMI_D7_Pin;
  GPIO_InitStruct.Mode = GPIO_MODE_AF_PP;
  GPIO_InitStruct.Pull = GPIO_NOPULL;
  GPIO_InitStruct.Speed = GPIO_SPEED_FREQ_LOW;
  GPIO_InitStruct.Alternate = GPIO_AF13_DCMI;
  HAL_GPIO_Init(GPIOE, &GPIO_InitStruct);

  /*Configure GPIO pin : QSPI_NCS_Pin */
  GPIO_InitStruct.Pin = QSPI_NCS_Pin;
  GPIO_InitStruct.Mode = GPIO_MODE_AF_PP;
  GPIO_InitStruct.Pull = GPIO_NOPULL;
  GPIO_InitStruct.Speed = GPIO_SPEED_FREQ_VERY_HIGH;
  GPIO_InitStruct.Alternate = GPIO_AF10_QUADSPI;
  HAL_GPIO_Init(QSPI_NCS_GPIO_Port, &GPIO_InitStruct);

  /*Configure GPIO pin : OTG_FS_VBUS_Pin */
  GPIO_InitStruct.Pin = OTG_FS_VBUS_Pin;
  GPIO_InitStruct.Mode = GPIO_MODE_INPUT;
  GPIO_InitStruct.Pull = GPIO_NOPULL;
  HAL_GPIO_Init(OTG_FS_VBUS_GPIO_Port, &GPIO_InitStruct);

  /*Configure GPIO pins : OTG_FS_P_Pin OTG_FS_N_Pin OTG_FS_ID_Pin */
  GPIO_InitStruct.Pin = OTG_FS_P_Pin|OTG_FS_N_Pin|OTG_FS_ID_Pin;
  GPIO_InitStruct.Mode = GPIO_MODE_AF_PP;
  GPIO_InitStruct.Pull = GPIO_NOPULL;
  GPIO_InitStruct.Speed = GPIO_SPEED_FREQ_VERY_HIGH;
  GPIO_InitStruct.Alternate = GPIO_AF10_OTG_FS;
  HAL_GPIO_Init(GPIOA, &GPIO_InitStruct);

  /*Configure GPIO pins : SAI2_MCLKA_Pin SAI2_SCKA_Pin SAI2_FSA_Pin SAI2_SDA_Pin */
  GPIO_InitStruct.Pin = SAI2_MCLKA_Pin|SAI2_SCKA_Pin|SAI2_FSA_Pin|SAI2_SDA_Pin;
  GPIO_InitStruct.Mode = GPIO_MODE_AF_PP;
  GPIO_InitStruct.Pull = GPIO_NOPULL;
  GPIO_InitStruct.Speed = GPIO_SPEED_FREQ_LOW;
  GPIO_InitStruct.Alternate = GPIO_AF10_SAI2;
  HAL_GPIO_Init(GPIOI, &GPIO_InitStruct);

  /*Configure GPIO pin : SAI2_SDB_Pin */
  GPIO_InitStruct.Pin = SAI2_SDB_Pin;
  GPIO_InitStruct.Mode = GPIO_MODE_AF_PP;
  GPIO_InitStruct.Pull = GPIO_NOPULL;
  GPIO_InitStruct.Speed = GPIO_SPEED_FREQ_LOW;
  GPIO_InitStruct.Alternate = GPIO_AF10_SAI2;
  HAL_GPIO_Init(SAI2_SDB_GPIO_Port, &GPIO_InitStruct);

  /*Configure GPIO pin : OTG_FS_PowerSwitchOn_Pin */
  GPIO_InitStruct.Pin = OTG_FS_PowerSwitchOn_Pin;
  GPIO_InitStruct.Mode = GPIO_MODE_OUTPUT_PP;
  GPIO_InitStruct.Pull = GPIO_NOPULL;
  GPIO_InitStruct.Speed = GPIO_SPEED_FREQ_LOW;
  HAL_GPIO_Init(OTG_FS_PowerSwitchOn_GPIO_Port, &GPIO_InitStruct);

  /*Configure GPIO pin : DCMI_D5_Pin */
  GPIO_InitStruct.Pin = DCMI_D5_Pin;
  GPIO_InitStruct.Mode = GPIO_MODE_AF_PP;
  GPIO_InitStruct.Pull = GPIO_NOPULL;
  GPIO_InitStruct.Speed = GPIO_SPEED_FREQ_LOW;
  GPIO_InitStruct.Alternate = GPIO_AF13_DCMI;
  HAL_GPIO_Init(DCMI_D5_GPIO_Port, &GPIO_InitStruct);

  /*Configure GPIO pins : ARDUINO_D7_Pin ARDUINO_D8_Pin LCD_DISP_Pin */
  GPIO_InitStruct.Pin = ARDUINO_D7_Pin|ARDUINO_D8_Pin|LCD_DISP_Pin;
  GPIO_InitStruct.Mode = GPIO_MODE_OUTPUT_PP;
  GPIO_InitStruct.Pull = GPIO_NOPULL;
  GPIO_InitStruct.Speed = GPIO_SPEED_FREQ_LOW;
  HAL_GPIO_Init(GPIOI, &GPIO_InitStruct);

  /*Configure GPIO pin : uSD_Detect_Pin */
  GPIO_InitStruct.Pin = uSD_Detect_Pin;
  GPIO_InitStruct.Mode = GPIO_MODE_INPUT;
  GPIO_InitStruct.Pull = GPIO_NOPULL;
  HAL_GPIO_Init(uSD_Detect_GPIO_Port, &GPIO_InitStruct);

  /*Configure GPIO pin : LCD_BL_CTRL_Pin */
  GPIO_InitStruct.Pin = LCD_BL_CTRL_Pin;
  GPIO_InitStruct.Mode = GPIO_MODE_OUTPUT_PP;
  GPIO_InitStruct.Pull = GPIO_NOPULL;
  GPIO_InitStruct.Speed = GPIO_SPEED_FREQ_LOW;
  HAL_GPIO_Init(LCD_BL_CTRL_GPIO_Port, &GPIO_InitStruct);

  /*Configure GPIO pin : DCMI_VSYNC_Pin */
  GPIO_InitStruct.Pin = DCMI_VSYNC_Pin;
  GPIO_InitStruct.Mode = GPIO_MODE_AF_PP;
  GPIO_InitStruct.Pull = GPIO_NOPULL;
  GPIO_InitStruct.Speed = GPIO_SPEED_FREQ_LOW;
  GPIO_InitStruct.Alternate = GPIO_AF13_DCMI;
  HAL_GPIO_Init(DCMI_VSYNC_GPIO_Port, &GPIO_InitStruct);

  /*Configure GPIO pin : OTG_FS_OverCurrent_Pin */
  GPIO_InitStruct.Pin = OTG_FS_OverCurrent_Pin;
  GPIO_InitStruct.Mode = GPIO_MODE_INPUT;
  GPIO_InitStruct.Pull = GPIO_NOPULL;
  HAL_GPIO_Init(OTG_FS_OverCurrent_GPIO_Port, &GPIO_InitStruct);

  /*Configure GPIO pin : SDMMC_D0_Pin */
  GPIO_InitStruct.Pin = SDMMC_D0_Pin;
  GPIO_InitStruct.Mode = GPIO_MODE_AF_PP;
  GPIO_InitStruct.Pull = GPIO_NOPULL;
  GPIO_InitStruct.Speed = GPIO_SPEED_FREQ_VERY_HIGH;
  GPIO_InitStruct.Alternate = GPIO_AF12_SDMMC1;
  HAL_GPIO_Init(SDMMC_D0_GPIO_Port, &GPIO_InitStruct);

  /*Configure GPIO pins : TP3_Pin NC2_Pin */
  GPIO_InitStruct.Pin = TP3_Pin|NC2_Pin;
  GPIO_InitStruct.Mode = GPIO_MODE_INPUT;
  GPIO_InitStruct.Pull = GPIO_NOPULL;
  HAL_GPIO_Init(GPIOH, &GPIO_InitStruct);

  /*Configure GPIO pin : ARDUINO_SCK_D13_Pin */
  GPIO_InitStruct.Pin = ARDUINO_SCK_D13_Pin;
  GPIO_InitStruct.Mode = GPIO_MODE_AF_PP;
  GPIO_InitStruct.Pull = GPIO_NOPULL;
  GPIO_InitStruct.Speed = GPIO_SPEED_FREQ_LOW;
  GPIO_InitStruct.Alternate = GPIO_AF5_SPI2;
  HAL_GPIO_Init(ARDUINO_SCK_D13_GPIO_Port, &GPIO_InitStruct);

  /*Configure GPIO pin : DCMI_PWR_EN_Pin */
  GPIO_InitStruct.Pin = DCMI_PWR_EN_Pin;
  GPIO_InitStruct.Mode = GPIO_MODE_OUTPUT_PP;
  GPIO_InitStruct.Pull = GPIO_NOPULL;
  GPIO_InitStruct.Speed = GPIO_SPEED_FREQ_LOW;
  HAL_GPIO_Init(DCMI_PWR_EN_GPIO_Port, &GPIO_InitStruct);

  /*Configure GPIO pins : DCMI_D4_Pin DCMI_D3_Pin DCMI_D0_Pin DCMI_D2_Pin
                           DCMI_D1_Pin */
  GPIO_InitStruct.Pin = DCMI_D4_Pin|DCMI_D3_Pin|DCMI_D0_Pin|DCMI_D2_Pin
                          |DCMI_D1_Pin;
  GPIO_InitStruct.Mode = GPIO_MODE_AF_PP;
  GPIO_InitStruct.Pull = GPIO_NOPULL;
  GPIO_InitStruct.Speed = GPIO_SPEED_FREQ_LOW;
  GPIO_InitStruct.Alternate = GPIO_AF13_DCMI;
  HAL_GPIO_Init(GPIOH, &GPIO_InitStruct);

  /*Configure GPIO pin : ARDUINO_PWM_CS_D10_Pin */
  GPIO_InitStruct.Pin = ARDUINO_PWM_CS_D10_Pin;
  GPIO_InitStruct.Mode = GPIO_MODE_AF_PP;
  GPIO_InitStruct.Pull = GPIO_NOPULL;
  GPIO_InitStruct.Speed = GPIO_SPEED_FREQ_LOW;
  GPIO_InitStruct.Alternate = GPIO_AF2_TIM5;
  HAL_GPIO_Init(ARDUINO_PWM_CS_D10_GPIO_Port, &GPIO_InitStruct);

  /*Configure GPIO pin : ARDUINO_PWM_D5_Pin */
  GPIO_InitStruct.Pin = ARDUINO_PWM_D5_Pin;
  GPIO_InitStruct.Mode = GPIO_MODE_AF_PP;
  GPIO_InitStruct.Pull = GPIO_NOPULL;
  GPIO_InitStruct.Speed = GPIO_SPEED_FREQ_LOW;
  GPIO_InitStruct.Alternate = GPIO_AF1_TIM1;
  HAL_GPIO_Init(ARDUINO_PWM_D5_GPIO_Port, &GPIO_InitStruct);

  /*Configure GPIO pin : LCD_INT_Pin */
  GPIO_InitStruct.Pin = LCD_INT_Pin;
  GPIO_InitStruct.Mode = GPIO_MODE_EVT_RISING;
  GPIO_InitStruct.Pull = GPIO_NOPULL;
  HAL_GPIO_Init(LCD_INT_GPIO_Port, &GPIO_InitStruct);

  /*Configure GPIO pin : CDJ_XCS_Pin */
  GPIO_InitStruct.Pin = CDJ_XCS_Pin;
  GPIO_InitStruct.Mode = GPIO_MODE_IT_FALLING;
  GPIO_InitStruct.Pull = GPIO_NOPULL;
  HAL_GPIO_Init(CDJ_XCS_GPIO_Port, &GPIO_InitStruct);

  /*Configure GPIO pin : ULPI_NXT_Pin */
  GPIO_InitStruct.Pin = ULPI_NXT_Pin;
  GPIO_InitStruct.Mode = GPIO_MODE_AF_PP;
  GPIO_InitStruct.Pull = GPIO_NOPULL;
  GPIO_InitStruct.Speed = GPIO_SPEED_FREQ_VERY_HIGH;
  GPIO_InitStruct.Alternate = GPIO_AF10_OTG_HS;
  HAL_GPIO_Init(ULPI_NXT_GPIO_Port, &GPIO_InitStruct);

  /*Configure GPIO pin : CDJ_CLK_Pin */
  GPIO_InitStruct.Pin = CDJ_CLK_Pin;
  GPIO_InitStruct.Mode = GPIO_MODE_IT_RISING;
  GPIO_InitStruct.Pull = GPIO_NOPULL;
  HAL_GPIO_Init(CDJ_CLK_GPIO_Port, &GPIO_InitStruct);

  /*Configure GPIO pins : ARDUINO_D4_Pin EXT_RST_Pin */
  GPIO_InitStruct.Pin = ARDUINO_D4_Pin|EXT_RST_Pin;
  GPIO_InitStruct.Mode = GPIO_MODE_OUTPUT_PP;
  GPIO_InitStruct.Pull = GPIO_NOPULL;
  GPIO_InitStruct.Speed = GPIO_SPEED_FREQ_LOW;
  HAL_GPIO_Init(GPIOG, &GPIO_InitStruct);

  /*Configure GPIO pin : CDJ_DATA_Pin */
  GPIO_InitStruct.Pin = CDJ_DATA_Pin;
  GPIO_InitStruct.Mode = GPIO_MODE_INPUT;
  GPIO_InitStruct.Pull = GPIO_PULLUP;
  HAL_GPIO_Init(CDJ_DATA_GPIO_Port, &GPIO_InitStruct);

  /*Configure GPIO pins : ARDUINO_A4_Pin ARDUINO_A5_Pin ARDUINO_A1_Pin ARDUINO_A2_Pin
                           ARDUINO_A3_Pin */
  GPIO_InitStruct.Pin = ARDUINO_A4_Pin|ARDUINO_A5_Pin|ARDUINO_A1_Pin|ARDUINO_A2_Pin
                          |ARDUINO_A3_Pin;
  GPIO_InitStruct.Mode = GPIO_MODE_ANALOG;
  GPIO_InitStruct.Pull = GPIO_NOPULL;
  HAL_GPIO_Init(GPIOF, &GPIO_InitStruct);

  /*Configure GPIO pins : ULPI_STP_Pin ULPI_DIR_Pin */
  GPIO_InitStruct.Pin = ULPI_STP_Pin|ULPI_DIR_Pin;
  GPIO_InitStruct.Mode = GPIO_MODE_AF_PP;
  GPIO_InitStruct.Pull = GPIO_NOPULL;
  GPIO_InitStruct.Speed = GPIO_SPEED_FREQ_VERY_HIGH;
  GPIO_InitStruct.Alternate = GPIO_AF10_OTG_HS;
  HAL_GPIO_Init(GPIOC, &GPIO_InitStruct);

  /*Configure GPIO pins : RMII_MDC_Pin RMII_RXD0_Pin RMII_RXD1_Pin */
  GPIO_InitStruct.Pin = RMII_MDC_Pin|RMII_RXD0_Pin|RMII_RXD1_Pin;
  GPIO_InitStruct.Mode = GPIO_MODE_AF_PP;
  GPIO_InitStruct.Pull = GPIO_NOPULL;
  GPIO_InitStruct.Speed = GPIO_SPEED_FREQ_VERY_HIGH;
  GPIO_InitStruct.Alternate = GPIO_AF11_ETH;
  HAL_GPIO_Init(GPIOC, &GPIO_InitStruct);

  /*Configure GPIO pin : PB2 */
  GPIO_InitStruct.Pin = GPIO_PIN_2;
  GPIO_InitStruct.Mode = GPIO_MODE_AF_PP;
  GPIO_InitStruct.Pull = GPIO_NOPULL;
  GPIO_InitStruct.Speed = GPIO_SPEED_FREQ_VERY_HIGH;
  GPIO_InitStruct.Alternate = GPIO_AF9_QUADSPI;
  HAL_GPIO_Init(GPIOB, &GPIO_InitStruct);

  /*Configure GPIO pins : QSPI_D1_Pin QSPI_D3_Pin QSPI_D0_Pin */
  GPIO_InitStruct.Pin = QSPI_D1_Pin|QSPI_D3_Pin|QSPI_D0_Pin;
  GPIO_InitStruct.Mode = GPIO_MODE_AF_PP;
  GPIO_InitStruct.Pull = GPIO_NOPULL;
  GPIO_InitStruct.Speed = GPIO_SPEED_FREQ_VERY_HIGH;
  GPIO_InitStruct.Alternate = GPIO_AF9_QUADSPI;
  HAL_GPIO_Init(GPIOD, &GPIO_InitStruct);

  /*Configure GPIO pin : RMII_RXER_Pin */
  GPIO_InitStruct.Pin = RMII_RXER_Pin;
  GPIO_InitStruct.Mode = GPIO_MODE_INPUT;
  GPIO_InitStruct.Pull = GPIO_NOPULL;
  HAL_GPIO_Init(RMII_RXER_GPIO_Port, &GPIO_InitStruct);

  /*Configure GPIO pins : RMII_REF_CLK_Pin RMII_MDIO_Pin RMII_CRS_DV_Pin */
  GPIO_InitStruct.Pin = RMII_REF_CLK_Pin|RMII_MDIO_Pin|RMII_CRS_DV_Pin;
  GPIO_InitStruct.Mode = GPIO_MODE_AF_PP;
  GPIO_InitStruct.Pull = GPIO_NOPULL;
  GPIO_InitStruct.Speed = GPIO_SPEED_FREQ_VERY_HIGH;
  GPIO_InitStruct.Alternate = GPIO_AF11_ETH;
  HAL_GPIO_Init(GPIOA, &GPIO_InitStruct);

  /*Configure GPIO pin : ARDUINO_A0_Pin */
  GPIO_InitStruct.Pin = ARDUINO_A0_Pin;
  GPIO_InitStruct.Mode = GPIO_MODE_ANALOG;
  GPIO_InitStruct.Pull = GPIO_NOPULL;
  HAL_GPIO_Init(ARDUINO_A0_GPIO_Port, &GPIO_InitStruct);

  /*Configure GPIO pins : DCMI_HSYNC_Pin PA6 */
  GPIO_InitStruct.Pin = DCMI_HSYNC_Pin|GPIO_PIN_6;
  GPIO_InitStruct.Mode = GPIO_MODE_AF_PP;
  GPIO_InitStruct.Pull = GPIO_NOPULL;
  GPIO_InitStruct.Speed = GPIO_SPEED_FREQ_LOW;
  GPIO_InitStruct.Alternate = GPIO_AF13_DCMI;
  HAL_GPIO_Init(GPIOA, &GPIO_InitStruct);

  /*Configure GPIO pins : ULPI_CLK_Pin ULPI_D0_Pin */
  GPIO_InitStruct.Pin = ULPI_CLK_Pin|ULPI_D0_Pin;
  GPIO_InitStruct.Mode = GPIO_MODE_AF_PP;
  GPIO_InitStruct.Pull = GPIO_NOPULL;
  GPIO_InitStruct.Speed = GPIO_SPEED_FREQ_VERY_HIGH;
  GPIO_InitStruct.Alternate = GPIO_AF10_OTG_HS;
  HAL_GPIO_Init(GPIOA, &GPIO_InitStruct);

  /*Configure GPIO pin : ARDUINO_PWM_D6_Pin */
  GPIO_InitStruct.Pin = ARDUINO_PWM_D6_Pin;
  GPIO_InitStruct.Mode = GPIO_MODE_AF_PP;
  GPIO_InitStruct.Pull = GPIO_NOPULL;
  GPIO_InitStruct.Speed = GPIO_SPEED_FREQ_LOW;
  GPIO_InitStruct.Alternate = GPIO_AF9_TIM12;
  HAL_GPIO_Init(ARDUINO_PWM_D6_GPIO_Port, &GPIO_InitStruct);

  /*Configure GPIO pins : ARDUINO_MISO_D12_Pin ARDUINO_MOSI_PWM_D11_Pin */
  GPIO_InitStruct.Pin = ARDUINO_MISO_D12_Pin|ARDUINO_MOSI_PWM_D11_Pin;
  GPIO_InitStruct.Mode = GPIO_MODE_AF_PP;
  GPIO_InitStruct.Pull = GPIO_NOPULL;
  GPIO_InitStruct.Speed = GPIO_SPEED_FREQ_LOW;
  GPIO_InitStruct.Alternate = GPIO_AF5_SPI2;
  HAL_GPIO_Init(GPIOB, &GPIO_InitStruct);

  /*Configure GPIO pin Output Level */
  HAL_GPIO_WritePin(OTG_FS_PowerSwitchOn_GPIO_Port, OTG_FS_PowerSwitchOn_Pin, GPIO_PIN_SET);

  /*Configure GPIO pin Output Level */
  HAL_GPIO_WritePin(GPIOI, ARDUINO_D7_Pin|ARDUINO_D8_Pin|LCD_DISP_Pin, GPIO_PIN_RESET);

  /*Configure GPIO pin Output Level */
  HAL_GPIO_WritePin(LCD_BL_CTRL_GPIO_Port, LCD_BL_CTRL_Pin, GPIO_PIN_RESET);

  /*Configure GPIO pin Output Level */
  HAL_GPIO_WritePin(DCMI_PWR_EN_GPIO_Port, DCMI_PWR_EN_Pin, GPIO_PIN_RESET);

  /*Configure GPIO pin Output Level */
  HAL_GPIO_WritePin(GPIOG, ARDUINO_D4_Pin|EXT_RST_Pin, GPIO_PIN_RESET);

  /* EXTI interrupt init*/
  HAL_NVIC_SetPriority(EXTI9_5_IRQn, 0, 0);
  HAL_NVIC_EnableIRQ(EXTI9_5_IRQn);

}

/* USER CODE BEGIN 4 */

void EXTI9_5_IRQHandler(void)
{
	if(__HAL_GPIO_EXTI_GET_IT(GPIO_PIN_6) != RESET)
		{
		if(HAL_GPIO_ReadPin(GPIOC, GPIO_PIN_7)==0)
			{
			buf[number_of_package%8][clock_CNT/8] = buf[number_of_package%8][clock_CNT/8]<<1;
			if(HAL_GPIO_ReadPin(GPIOG, GPIO_PIN_6)==1)
				{
				buf[number_of_package%8][clock_CNT/8] = buf[number_of_package%8][clock_CNT/8]+1;
				}
			clock_CNT++;
			}
    __HAL_GPIO_EXTI_CLEAR_IT(GPIO_PIN_6);
    HAL_GPIO_EXTI_Callback(GPIO_PIN_6);
		}
else if(__HAL_GPIO_EXTI_GET_IT(GPIO_PIN_7) != RESET)
		{
		if(HAL_GPIO_ReadPin(GPIOC, GPIO_PIN_6)==1)
			{
			if(buf[number_of_package%8][0]==0)
				{
				number_of_package = 1;
				}
			else
				{
				number_of_package++;
				}
			clock_CNT = 0;
			}
    __HAL_GPIO_EXTI_CLEAR_IT(GPIO_PIN_7);
    HAL_GPIO_EXTI_Callback(GPIO_PIN_7);
		}
}

/* USER CODE END 4 */

void Error_Handler(void)
{
  while(1)
  {
  }
}

/************************ (C) COPYRIGHT STMicroelectronics *****END OF FILE****/
